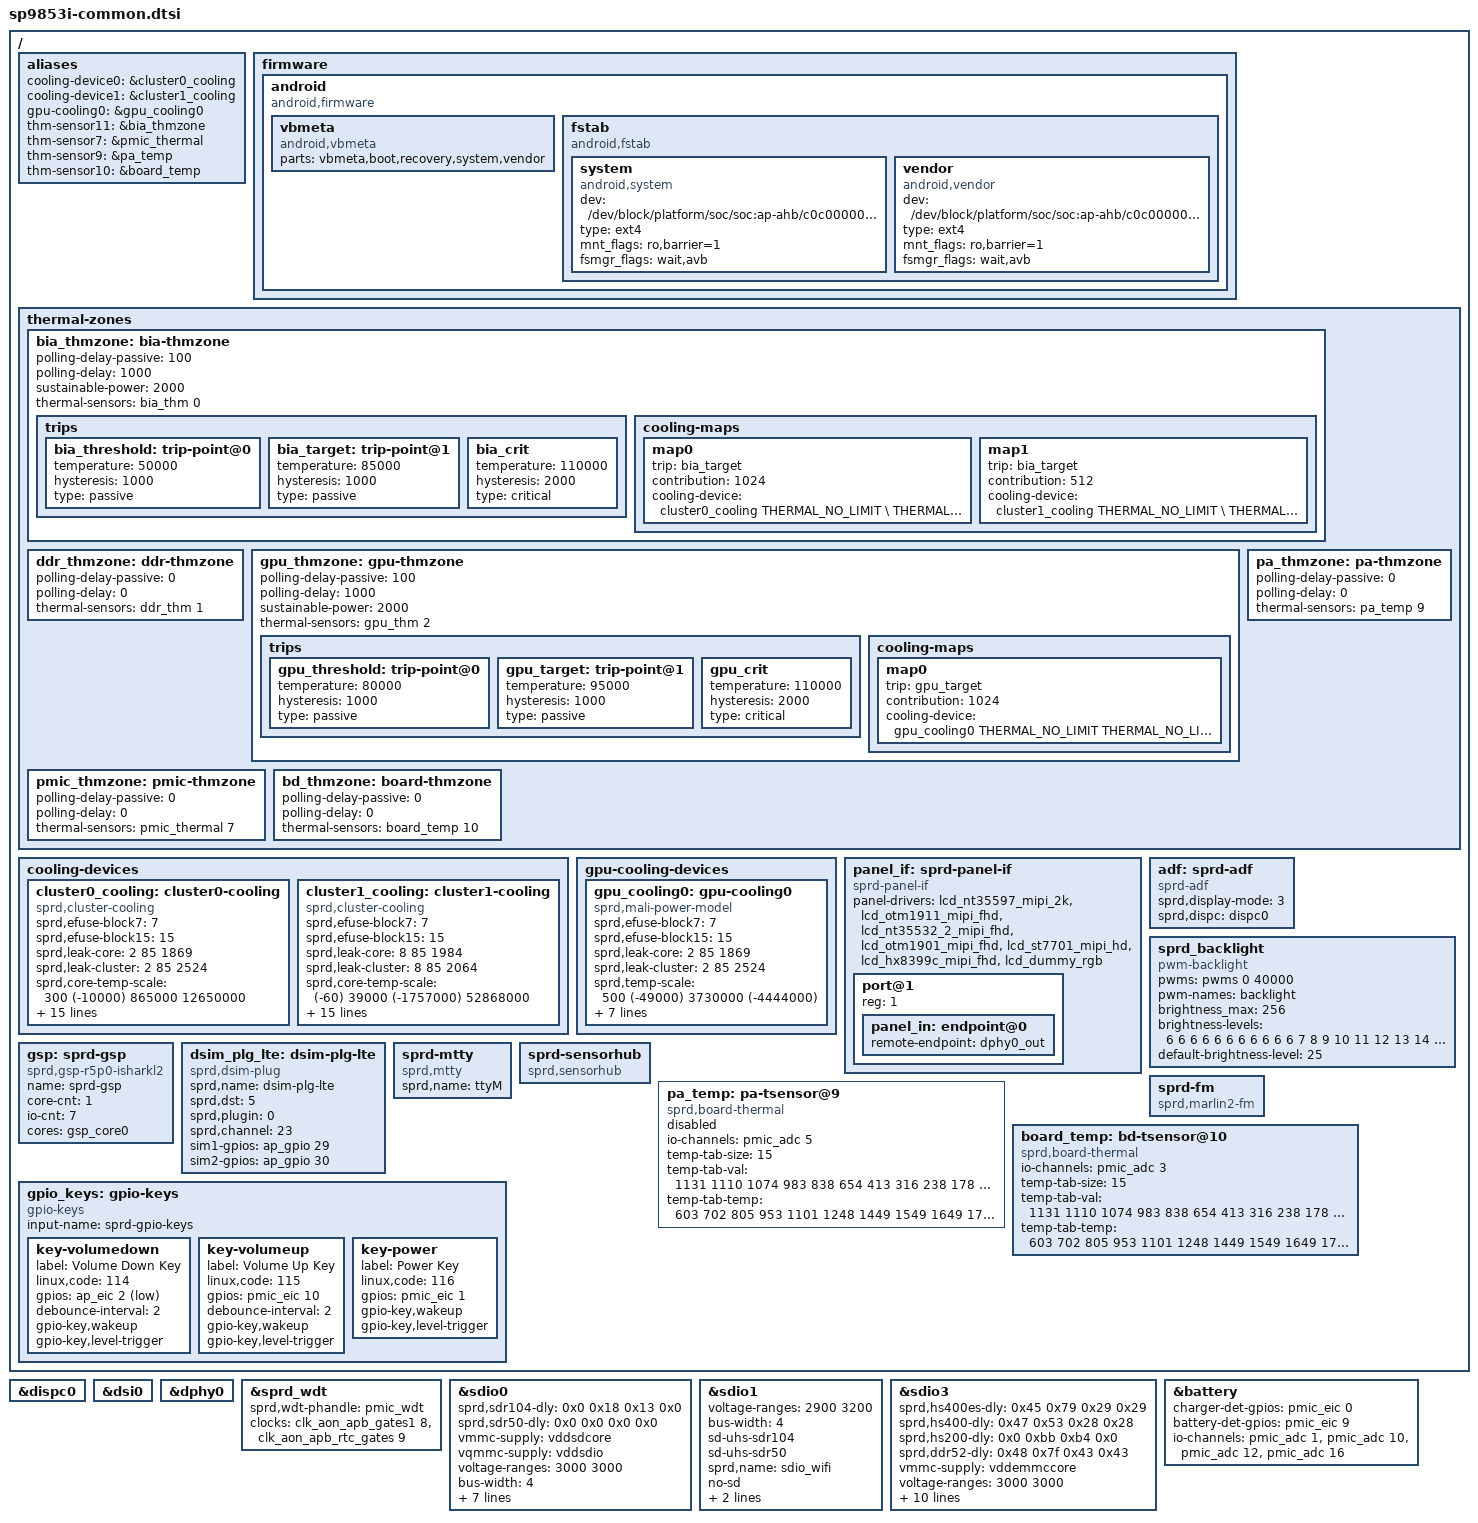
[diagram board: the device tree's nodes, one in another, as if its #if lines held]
/*
 * Spreadtrum SP98x0 board common DTS file
 *
 * Copyright (C) 2016, Spreadtrum Communications Inc.
 *
 * This file is licensed under a dual GPLv2 or X11 license.
 */

#ifdef CONFIG_MOBILEVISOR
#include "irq-vmm-sc9853.h"
#include "bia-vmm.dtsi"
#else
#include "irq-hw-sc9853.h"
#include "bia.dtsi"
#endif
#include "sc9853i.dtsi"
#include "sc2731.dtsi"
#include "lcd/lcd_nt35597_mipi_2k.dtsi"
#include "lcd/lcd_otm1911_mipi_fhd.dtsi"
#include "lcd/lcd_hx8399c_mipi_fhd.dtsi"
#include "lcd/lcd_nt35532_2_mipi.dtsi"
#include "lcd/lcd_st7701_mipi.dtsi"
#include "lcd/lcd_otm1901_mipi_fhd.dtsi"
#include "lcd/lcd_dummy_rgb.dtsi"
#include "sprd-battery.dtsi"
#include <dt-bindings/thermal/thermal.h>

/ {

	aliases {
		cooling-device0 = &cluster0_cooling;
		cooling-device1 = &cluster1_cooling;
		gpu-cooling0 = &gpu_cooling0;
		thm-sensor11 = &bia_thmzone;
		thm-sensor7 = &pmic_thermal;
		thm-sensor9 = &pa_temp;
		thm-sensor10 = &board_temp;
	};

	firmware {
		android {
			compatible = "android,firmware";

			vbmeta {
				compatible = "android,vbmeta";
				parts = "vbmeta,boot,recovery,system,vendor";
			};
			fstab {
				compatible = "android,fstab";
				system {
					compatible = "android,system";
					dev = "/dev/block/platform/soc/soc:ap-ahb/c0c00000.sdio/by-name/system";
					type = "ext4";
					mnt_flags = "ro,barrier=1";
					fsmgr_flags = "wait,avb";
				};
				vendor {
					compatible = "android,vendor";
					dev = "/dev/block/platform/soc/soc:ap-ahb/c0c00000.sdio/by-name/vendor";
					type = "ext4";
					mnt_flags = "ro,barrier=1";
					fsmgr_flags = "wait,avb";
				};
			};
		};
	};

	thermal-zones {

		bia_thmzone: bia-thmzone {
			polling-delay-passive = <100>;
			polling-delay = <1000>;
			sustainable-power = <2000>;
			thermal-sensors = <&bia_thm  0>;
			trips {
				bia_threshold: trip-point@0 {
					temperature = <50000>;
					hysteresis = <1000>;
					type = "passive";
				};
				bia_target: trip-point@1 {
					temperature = <85000>;
					hysteresis = <1000>;
					type = "passive";
				};
				bia_crit: bia_crit {
					temperature = <110000>;
					hysteresis = <2000>;
					type = "critical";
				};
			};
			cooling-maps {
				map0 {
					trip = <&bia_target>;
					contribution = <1024>;
					cooling-device =
					<&cluster0_cooling THERMAL_NO_LIMIT \
					THERMAL_NO_LIMIT>;
				};
				map1 {
					trip = <&bia_target>;
					contribution = <512>;
					cooling-device =
					<&cluster1_cooling THERMAL_NO_LIMIT \
					THERMAL_NO_LIMIT>;
				};
			};
		};

		ddr_thmzone: ddr-thmzone {
			polling-delay-passive = <0>;
			polling-delay = <0>;
			thermal-sensors = <&ddr_thm  1>;
		};

		gpu_thmzone: gpu-thmzone {
			polling-delay-passive = <100>;
			polling-delay = <1000>;
			sustainable-power = <2000>;
			thermal-sensors = <&gpu_thm  2>;
			trips {
				gpu_threshold: trip-point@0 {
					temperature = <80000>;
					hysteresis = <1000>;
					type = "passive";
				};
				gpu_target: trip-point@1 {
					temperature = <95000>;
					hysteresis = <1000>;
					type = "passive";
				};
				gpu_crit: gpu_crit {
					temperature = <110000>;
					hysteresis = <2000>;
					type = "critical";
				};
			};
			cooling-maps {
				map0 {
					trip = <&gpu_target>;
					contribution = <1024>;
					cooling-device =
					<&gpu_cooling0
						THERMAL_NO_LIMIT
						THERMAL_NO_LIMIT>;
				};
			};
		};

		pmic_thmzone: pmic-thmzone {
			polling-delay-passive = <0>;
			polling-delay = <0>;
			thermal-sensors = <&pmic_thermal 7>;
		};

		pa_thmzone: pa-thmzone {
			polling-delay-passive = <0>;
			polling-delay = <0>;
			thermal-sensors = <&pa_temp  9>;
		};

		bd_thmzone: board-thmzone {
			polling-delay-passive = <0>;
			polling-delay = <0>;
			thermal-sensors = <&board_temp  10>;
		};
	};

	cooling-devices {
		cluster0_cooling: cluster0-cooling {
			compatible = "sprd,cluster-cooling";
			#cooling-cells = <2>; /* min followed by max */
			sprd,efuse-block7 = <7>;
			sprd,efuse-block15 = <15>;
			/* core_leak =                             */
			/*(LIT_LEAK[4:0]+1) x 2mA x 0.85V x 18.69% */
			sprd,leak-core = <2 85 1869>;
			/* cluster_leak =                           */
			/* (LIT_LEAK[4:0]+1) x 2mA x 0.85V x 25.24% */
			sprd,leak-cluster = <2 85 2524>;
			/*core Tscale = aT^3 + bT^2 + cT +di   */
			sprd,core-temp-scale =
			/* a*10^7   b*10^7      c*10^7     d*10^7 */
			<  300      (-10000)   865000    12650000>;
			/*core Vscale = eV^3 + fV^2 + gV + h */
			sprd,core-voltage-scale =
			/* e*10^2   f*10^2     g*10^2  h*10^2*/
			<  2388     (-5762)    4888    (-1373)>;
			/*cluster Tscale = aT^3 + bT^2 + cT +di   */
			sprd,cluster-temp-scale =
			/* a*10^7   b*10^7      c*10^7     d*10^7 */
			<  (-80)    94000       (-3491000) 135010000>;
			/*cluster Vscale = eV^3 + fV^2 + gV + h */
			sprd,cluster-voltage-scale =
			/* e*10^2   f*10^2     g*10^2  h*10^2*/
			<  6777     (-17177)   15548   (-4603)>;
			sprd,efuse-switch = <0>;
			sprd,hotplug-period = <10>;
			sprd,min-cpufreq = <936000>;
			sprd,min-cpunum = <3>;
			/*resistance junction to ambient(℃/W) */
			sprd,resistance-ja = <13>;
			sprd,core-base = <31>;
			sprd,cluster-base = <10>;
			sprd,dynamic-core =
			/*Pdynperghz*10    Freq     Vbase  */
			< 3302           1000     1200>;
			sprd,dynamic-cluster =
			/*Pdynperghz*10    Freq     Vbase  */
			< 403           1000     1200>;
		};
		cluster1_cooling: cluster1-cooling {
			compatible = "sprd,cluster-cooling";
			#cooling-cells = <2>; /* min followed by max */
			sprd,efuse-block7 = <7>;
			sprd,efuse-block15 = <15>;
			/* core_leak =                             */
			/*(LIT_LEAK[4:0]+1) x 2mA x 0.85V x 18.69% */
			sprd,leak-core = <8 85 1984>;
			/* cluster_leak =                           */
			/* (LIT_LEAK[4:0]+1) x 2mA x 0.85V x 25.24% */
			sprd,leak-cluster = <8 85 2064>;
			/*core Tscale = aT^3 + bT^2 + cT +d  */
			sprd,core-temp-scale =
			/* a*10^7   b*10^7	c*10^7	   d*10^7*/
			<  (-60)    39000   (-1757000) 52868000>;
			/* core  Vscale = eV^3 + fV^2 + gV + h */
			sprd,core-voltage-scale =
			/* e*10^2  f*10^2     g*10^2  h*10^2*/
			<  3727    (-9513)    8305      (-2390)>;
			/*cluster Tscale = aT^3 + bT^2 + cT +di   */
			sprd,cluster-temp-scale =
			/* a*10^7   b*10^7      c*10^7     d*10^7 */
			<  600      (-35000)    2943000    41477000>;
			/*cluster Vscale = eV^3 + fV^2 + gV + h */
			sprd,cluster-voltage-scale =
			/* e*10^2   f*10^2     g*10^2  h*10^2*/
			<  3218     (-6790)    5624    (-1500)>;
			sprd,efuse-switch = <0>;
			sprd,hotplug-period = <10>;
			sprd,min-cpufreq = <624000>;
			sprd,min-cpunum = <0>;
			/*resistance junction to ambient(℃/W) */
			sprd,resistance-ja = <13>;
			sprd,core-base = <31>;
			sprd,cluster-base = <10>;
			sprd,dynamic-core =
			/* Pdynperghz*10    Freq     Vbase */
			<  3302          1000     1200>;
			sprd,dynamic-cluster =
			/* Pdynperghz*10    Freq     Vbase */
			<  403           1000     1200>;
		};
	};

	gpu-cooling-devices {
		gpu_cooling0: gpu-cooling0 {
			compatible = "sprd,mali-power-model";
			#cooling-cells = <2>;
			sprd,efuse-block7 = <7>;
			sprd,efuse-block15 = <15>;
			/* core_leak =                             */
			/*(LIT_LEAK[4:0]+1) x 2mA x 0.85V x 18.69% */
			sprd,leak-core = <2 85 1869>;
			/* cluster_leak =                           */
			/* (LIT_LEAK[4:0]+1) x 2mA x 0.85V x 25.24% */
			sprd,leak-cluster = <2 85 2524>;
			/*Tscale = aT^3 + bT^2 + cT +di   */
			sprd,temp-scale =
			/* a*10^7   b*10^7      c*10^7     d*10^7 */
			<  500     (-49000)   3730000    (-4444000)>;
			/*Vscale = eV^3 + fV^2 + gV + h */
			sprd,voltage-scale =
			/* e*10^2   f*10^2     g*10^2  h*10^2*/
			<  15623     (-42221)    40104    (-12970)>;
			sprd,hotplug-period = <0>;
			sprd,core-base = <68>;
			sprd,cluster-base = <68>;
			sprd,dynamic-core =
			/*Pdynperghz    Freq     Vbase  */
			< 2640           768     1050>;
			sprd,dynamic-cluster =
			/*Pdynperghz    Freq     Vbase  */
			< 1933           768     1050>;
		};
	};

	panel_if: sprd-panel-if {
		compatible = "sprd-panel-if";
		#address-cells = <1>;
		#size-cells = <0>;
		panel-drivers = <
			&lcd_nt35597_mipi_2k
			&lcd_otm1911_mipi_fhd
			&lcd_nt35532_2_mipi_fhd
			&lcd_otm1901_mipi_fhd
			&lcd_st7701_mipi_hd
			&lcd_hx8399c_mipi_fhd
			&lcd_dummy_rgb
		>;

		/* input port */
		port@1 {
		/* WARNING: the reg property must be 1 ! */
			reg = <1>;
			panel_in: endpoint@0 {
				remote-endpoint = <&dphy0_out>;
			};
		};
	};

	adf: sprd-adf {
		compatible = "sprd-adf";
		status = "okay";
		sprd,display-mode = <3>;
		sprd,dispc = <&dispc0>;
	};

	sprd_backlight: sprd_backlight {
		compatible = "pwm-backlight";
		pwms = <&pwms 0 40000>;
		pwm-names = "backlight";
		brightness_max = <256>;
		brightness-levels=<
			  6   6   6   6
			  6   6   6   6   6   6   6   7   8   9
			 10  11  12  13  14  15  16  17  18  19
			 20  21  22  23  24  25  26  27  28  29
			 30  31  32  33  34  35  36  37  38  39
			 40  41  42  43  44  45  46  47  48  49
			 50  51  52  53  54  55  56  57  58  59
			 60  61  62  63  64  65  66  67  68  69
			 70  71  72  73  74  75  76  77  78  79
			 80  81  82  83  84  85  86  87  88  89
			 90  91  92  93  94  95  96  97  98  99
			100 101 102 103 104 105 106 107 108 109
			110 111 112 113 114 115 116 117 118 119
			120 121 122 123 124 125 126 127 128 129
			130 131 132 133 134 135 136 137 138 139
			140 141 142 143 144 145 146 147 148 149
			150 151 152 153 154 155 156 157 158 159
			160 161 162 163 164 165 166 167 168 169
			170 171 172 173 174 175 176 177 178 179
			180 181 182 183 184 185 186 187 188 189
			190 191 192 193 194 195 196 197 198 199
			200 201 202 203 204 205 206 207 208 209
			210 211 212 213 214 215 216 217 218 219
			220 221 222 223 224 225 226 227 228 229
			230 231 232 233 234 235 236 237 238 239
			240 241 242 243 244 245 246 247 248 249
			250 251
			>;
		default-brightness-level = <25>;
	};

	gsp: sprd-gsp {
		compatible = "sprd,gsp-r5p0-isharkl2";
		name = "sprd-gsp";
		core-cnt = <1>;
		io-cnt = <7>;
		cores = <&gsp_core0>;
	};

	dsim_plg_lte: dsim-plg-lte {
		compatible = "sprd,dsim-plug";
		sprd,name = "dsim-plg-lte";
		sprd,dst = <5>;
		sprd,plugin = <0>;
		sprd,channel = <23>;
		sim1-gpios = <&ap_gpio 29 0>;
		sim2-gpios = <&ap_gpio 30 0>;
	};

	sprd-mtty {
		compatible = "sprd,mtty";
		sprd,name = "ttyM";
	};

	sprd-sensorhub {
		compatible = "sprd,sensorhub";
	};

	pa_temp:pa-tsensor@9 {
		compatible = "sprd,board-thermal";
		#thermal-sensor-cells = <1>;
		io-channels = <&pmic_adc 5>;
		io-channel-names = "adc_temp";
		temp-tab-size = <15>;
		temp-tab-val = <1131 1110 1074 983 838 654 413 316
				238 178 133 100 75 57 43>;
		temp-tab-temp = <603 702 805 953 1101 1248 1449 1549
				1649 1749 1849 1949 2049 2149 2249>;
	};

	sprd-fm {
		compatible  = "sprd,marlin2-fm";
	};

	board_temp:bd-tsensor@10 {
		compatible = "sprd,board-thermal";
		#thermal-sensor-cells = <1>;
		io-channels = <&pmic_adc 3>;
		io-channel-names = "adc_temp";
		temp-tab-size = <15>;
		temp-tab-val = <1131 1110 1074 983 838 654 413 316
				238 178 133 100 75 57 43>;
		temp-tab-temp = <603 702 805 953 1101 1248 1449 1549
				1649 1749 1849 1949 2049 2149 2249>;
	};

	gpio_keys:gpio-keys {
		compatible = "gpio-keys";
		input-name = "sprd-gpio-keys";
		status = "okay";

		key-volumedown {
			label = "Volume Down Key";
			linux,code = <114>;
			gpios = <&ap_eic 2 1>;
			debounce-interval = <2>;
			gpio-key,wakeup;
			gpio-key,level-trigger;
		};

		key-volumeup {
			label = "Volume Up Key";
			linux,code = <115>;
			gpios = <&pmic_eic 10 0>;
			debounce-interval = <2>;
			gpio-key,wakeup;
			gpio-key,level-trigger;
		};

		key-power {
			label = "Power Key";
			linux,code = <116>;
			gpios = <&pmic_eic 1 0>;
			gpio-key,wakeup;
			gpio-key,level-trigger;
		};

	};
};

&dispc0 {
	status = "okay";
};

&dsi0 {
	status = "okay";
};

&dphy0 {
	status = "okay";
};

&sprd_wdt {
	sprd,wdt-phandle = <&pmic_wdt>;
	clocks = <&clk_aon_apb_gates1 8>, <&clk_aon_apb_rtc_gates 9>;
};

&sdio0 {
	sprd,sdr104-dly = <0x0 0x18 0x13 0x0>;
	sprd,sdr50-dly = <0x0 0x0 0x0 0x0>;
	vmmc-supply = <&vddsdcore>;
	vqmmc-supply = <&vddsdio>;
	voltage-ranges = <3000 3000>;
	bus-width = <4>;
	sd-uhs-sdr104;
	sd-uhs-sdr50;
	pinctrl-names = "sd0_sl_0","sd0_sl_1";
	pinctrl-0 = <&vio_sd0_sl_0>;
	pinctrl-1 = <&vio_sd0_sl_1>;
	sprd,name = "sdio_sd";
	no-sdio;
	no-mmc;
	status = "okay";
};

&sdio1 {
	voltage-ranges = <2900 3200>;
	bus-width = <4>;
	/* TODO: Need HW offer delays if need to supprt uhs mode */
	sd-uhs-sdr104;
	sd-uhs-sdr50;
	sprd,name = "sdio_wifi";
	no-sd;
	no-mmc;
	keep-power-in-suspend;
	status = "okay";
};

&sdio3 {
	sprd,hs400es-dly = <0x45 0x79 0x29 0x29>;
	sprd,hs400-dly = <0x47 0x53 0x28 0x28>;
	sprd,hs200-dly = <0x0 0xbb 0xb4 0x0>;
	sprd,ddr52-dly = <0x48 0x7f 0x43 0x43>;
	vmmc-supply = <&vddemmccore>;
	voltage-ranges = <3000 3000>;
	bus-width = <8>;
	non-removable;
	cap-mmc-hw-reset;
	mmc-hs400-enhanced-strobe;
	mmc-hs400-1_8v;
	mmc-hs200-1_8v;
	mmc-ddr-1_8v;
	sprd,name = "sdio_emmc";
	no-sdio;
	no-sd;
	status = "okay";
};

&battery {
	charger-det-gpios = <&pmic_eic 0 0>;
	battery-det-gpios = <&pmic_eic 9 0>;
	io-channels = <&pmic_adc 1>,<&pmic_adc 10>,
			<&pmic_adc 12>,<&pmic_adc 16>;
	io-channel-names = "adc_temp","adc_vbat",
			"adc_vchg","adc_isense";
	status = "okay";
};

&pa_temp {
	status = "disabled";
};
